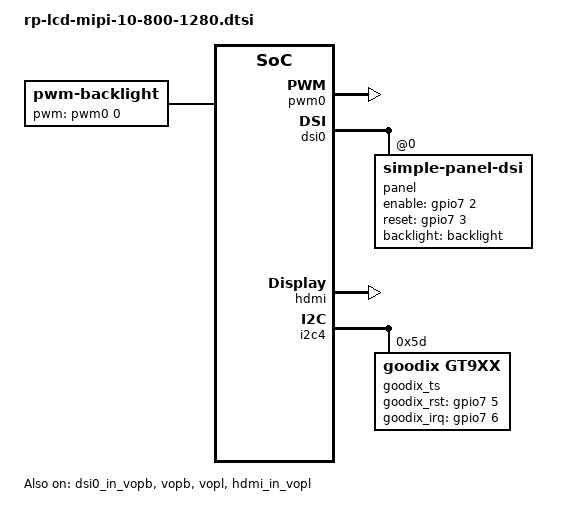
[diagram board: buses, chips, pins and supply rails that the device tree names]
/ {
	display-subsystem {
		status = "okay";

		ports = <&vopb_out>, <&vopl_out>;
		logo-memory-region = <&drm_logo>;

		route {
			route_edp: route-edp {
				status = "disabled";
				logo,uboot = "logo.bmp";
				logo,kernel = "logo.bmp";
				logo,mode = "center";
				charge_logo,mode = "center";
				connect = <&vopb_out_edp>;
			};

			route_dsi0: route-dsi0 {
				status = "disabled";
				logo,uboot = "logo.bmp";
				logo,kernel = "logo.bmp";
				logo,mode = "center";
				charge_logo,mode = "center";
				connect = <&vopb_out_dsi0>;
			};

			route_lvds: route-lvds {
				status = "disabled";
				logo,uboot = "logo.bmp";
				logo,kernel = "logo.bmp";
				logo,mode = "center";
				charge_logo,mode = "center";
				connect = <&vopb_out_lvds>;
			};

			route_hdmi: route-hdmi {
				status = "disabled";
				logo,uboot = "logo.bmp";
				logo,kernel = "logo.bmp";
				logo,mode = "center";
				charge_logo,mode = "center";
				connect = <&vopl_out_hdmi>;
			};
		};
	};
	
	backlight: backlight {
		status = "okay";
		compatible = "pwm-backlight";
		pwms = <&pwm0 0 25000 0>;
		brightness-levels = <
			  0   1   2   3   4   5   6   7
			  8   9  10  11  12  13  14  15
			 16  17  18  19  20  21  22  23
			 24  25  26  27  28  29  30  31
			 32  33  34  35  36  37  38  39
			 40  41  42  43  44  45  46  47
			 48  49  50  51  52  53  54  55
			 56  57  58  59  60  61  62  63
			 64  65  66  67  68  69  70  71
			 72  73  74  75  76  77  78  79
			 80  81  82  83  84  85  86  87
			 88  89  90  91  92  93  94  95
			 96  97  98  99 100 101 102 103
			104 105 106 107 108 109 110 111
			112 113 114 115 116 117 118 119
			120 121 122 123 124 125 126 127
			128 129 130 131 132 133 134 135
			136 137 138 139 140 141 142 143
			144 145 146 147 148 149 150 151
			152 153 154 155 156 157 158 159
			160 161 162 163 164 165 166 167
			168 169 170 171 172 173 174 175
			176 177 178 179 180 181 182 183
			184 185 186 187 188 189 190 191
			192 193 194 195 196 197 198 199
			200 201 202 203 204 205 206 207
			208 209 210 211 212 213 214 215
			216 217 218 219 220 221 222 223
			224 225 226 227 228 229 230 231
			232 233 234 235 236 237 238 239
			240 241 242 243 244 245 246 247
			248 249 250 251 252 253 254 255>;
		default-brightness-level = <255>;
	};
};


&pwm0 {
        status = "okay";
};

&dsi0 {
        status = "okay";
        rockchip,lane-rate = <480>;

        panel: panel {
                compatible = "simple-panel-dsi";
                reg = <0>;
                backlight = <&backlight>;
		cmd_later_reset = <0>;
                enable-gpios = <&gpio7 2 GPIO_ACTIVE_HIGH>;
                reset-gpios = <&gpio7 3 GPIO_ACTIVE_HIGH>;
                dsi,flags = <(MIPI_DSI_MODE_VIDEO | MIPI_DSI_MODE_VIDEO_BURST |
                                MIPI_DSI_MODE_LPM | MIPI_DSI_MODE_EOT_PACKET)>;
                dsi,format = <MIPI_DSI_FMT_RGB888>;
                dsi,lanes = <4>;
                reset-delay-ms = <20>;
                init-delay-ms = <20>;
                enable-delay-ms = <120>;
                prepare-delay-ms = <120>;
				
					
                status = "okay";
		
		panel-init-sequence = [
			15 00 02 e0 00
			15 00 02 e1 93	///0x09>;
			15 00 02 e2 65
			15 00 02 e3 f8
			15 00 02 80 03	///0x02>;	//0x02 = 3lane,0x03 = 4lane
			15 00 02 e0 04
			15 00 02 2d 03
			15 00 02 e0 01
			15 00 02 00 00
			15 00 02 01 5c
			15 00 02 03 00
			15 00 02 04 68
			15 00 02 17 00
			15 00 02 18 d7
			15 00 02 19 01
			15 00 02 1a 00
			15 00 02 1b d7
			15 00 02 1c 01
			15 00 02 1f 6b
			15 00 02 20 29
			15 00 02 21 29
			15 00 02 22 7e
			15 00 02 37 59
			15 00 02 35 28
			15 00 02 38 05
			15 00 02 39 08
			15 00 02 3a 12
			15 00 02 3c 7e
			15 00 02 3d ff
			15 00 02 3e ff
			15 00 02 3f 7f
			15 00 02 40 06
			15 00 02 41 a0
			15 00 02 43 1e
			15 00 02 44 0b
			15 00 02 55 01
			15 00 02 56 01
			15 00 02 57 69
			15 00 02 58 0a
			15 00 02 59 2a
			15 00 02 5a 29
			15 00 02 5b 15
			15 00 02 5c 16
			15 00 02 5d 64
			15 00 02 5e 50
			15 00 02 5f 43
			15 00 02 60 38
			15 00 02 61 36
			15 00 02 62 29
			15 00 02 63 2f
			15 00 02 64 1b
			15 00 02 65 35
			15 00 02 66 35
			15 00 02 67 35
			15 00 02 68 53
			15 00 02 69 41
			15 00 02 6a 47
			15 00 02 6b 38
			15 00 02 6c 34
			15 00 02 6d 27
			15 00 02 6e 19
			15 00 02 6f 12
			15 00 02 70 64
			15 00 02 71 50
			15 00 02 72 43
			15 00 02 73 38
			15 00 02 74 36
			15 00 02 75 29
			15 00 02 76 2f
			15 00 02 77 1b
			15 00 02 78 35
			15 00 02 79 35
			15 00 02 7a 35
			15 00 02 7b 53
			15 00 02 7c 41
			15 00 02 7d 47
			15 00 02 7e 38
			15 00 02 7f 34
			15 00 02 80 27
			15 00 02 81 19
			15 00 02 82 12
			15 00 02 e0 02
			15 00 02 00 53
			15 00 02 01 5f
			15 00 02 02 5f
			15 00 02 03 5f
			15 00 02 04 5f
			15 00 02 05 51
			15 00 02 06 77
			15 00 02 07 57
			15 00 02 08 4f
			15 00 02 09 5f
			15 00 02 0a 4d
			15 00 02 0b 4b
			15 00 02 0c 5f
			15 00 02 0d 49
			15 00 02 0e 47
			15 00 02 0f 45
			15 00 02 10 41
			15 00 02 11 5f
			15 00 02 12 5f
			15 00 02 13 5f
			15 00 02 14 5f
			15 00 02 15 5f
			15 00 02 16 52
			15 00 02 17 5f
			15 00 02 18 5f
			15 00 02 19 5f
			15 00 02 1a 5f
			15 00 02 1b 50
			15 00 02 1c 77
			15 00 02 1d 57
			15 00 02 1e 4e
			15 00 02 1f 5f
			15 00 02 20 4c
			15 00 02 21 4a
			15 00 02 22 5f
			15 00 02 23 48
			15 00 02 24 46
			15 00 02 25 44
			15 00 02 26 40
			15 00 02 27 5f
			15 00 02 28 5f
			15 00 02 29 5f
			15 00 02 2a 5f
			15 00 02 2b 5f
			15 00 02 2c 12
			15 00 02 2d 1f
			15 00 02 2e 1f
			15 00 02 2f 1f
			15 00 02 30 1f
			15 00 02 31 00
			15 00 02 32 17
			15 00 02 33 17
			15 00 02 34 04
			15 00 02 35 1f
			15 00 02 36 06
			15 00 02 37 08
			15 00 02 38 1f
			15 00 02 39 0a
			15 00 02 3a 0c
			15 00 02 3b 0e	///0x01>;
			15 00 02 3c 10
			15 00 02 3d 1f
			15 00 02 3e 1f
			15 00 02 3f 1f
			15 00 02 40 1f
			15 00 02 41 1f
			15 00 02 42 13
			15 00 02 43 1f
			15 00 02 44 1f
			15 00 02 45 1f
			15 00 02 46 1f
			15 00 02 47 01
			15 00 02 48 17
			15 00 02 49 17
			15 00 02 4a 05
			15 00 02 4b 1f
			15 00 02 4c 07
			15 00 02 4d 09
			15 00 02 4e 1f
			15 00 02 4f 0b
			15 00 02 50 0d
			15 00 02 51 0f
			15 00 02 52 11
			15 00 02 53 1f
			15 00 02 54 1f
			15 00 02 55 1f
			15 00 02 56 1f
			15 00 02 57 1f
			15 00 02 58 00
			15 00 02 59 00
			15 00 02 5a 00
			15 00 02 5b 10
			15 00 02 5c 04
			15 00 02 5d 40
			15 00 02 5e 00
			15 00 02 5f 00
			15 00 02 60 40
			15 00 02 61 03
			15 00 02 62 04
			15 00 02 63 70
			15 00 02 64 70
			15 00 02 65 75
			15 00 02 66 0b
			15 00 02 67 b4
			15 00 02 68 06
			15 00 02 69 70
			15 00 02 6a 70
			15 00 02 6b 04
			15 00 02 6c 00
			15 00 02 6d 04
			15 00 02 6e 00
			15 00 02 6f 88
			15 00 02 70 00
			15 00 02 71 00
			15 00 02 72 06
			15 00 02 73 7b
			15 00 02 74 00
			15 00 02 75 bc
			15 00 02 76 00
			15 00 02 77 05
			15 00 02 78 2a
			15 00 02 79 00
			15 00 02 7a 00
			15 00 02 7b 00
			15 00 02 7c 00
			15 00 02 7d 03
			15 00 02 7e 7b
			15 00 02 e0 04
			15 00 02 09 10
			15 00 02 0e 48
			15 00 02 2b 2b
			15 01 02 2e 44
			15 00 02 e0 00
			15 00 02 e6 02
			15 00 02 e7 06
			
			05 78 01 11
			05 78 01 29
			15 0a 02 35 00
		];
		panel-exit-sequence = [
			05 00 01 28
			05 78 01 10
		];

                disp_timings: display-timings {
                        native-mode = <&timing0>;

                        timing0: timing0 {
                                clock-frequency = <68000000>;
                                hactive = <800>;
                                vactive = <1280>;
                                hback-porch = <18>;
                                hfront-porch = <18>;
                                vback-porch = <8>;
                                vfront-porch = <24>;
                                hsync-len = <20>;
                                vsync-len = <4>;
                                hsync-active = <0>;
                                vsync-active = <0>;
                                de-active = <0>;
                                pixelclk-active = <0>;
                        };
                };
        };
};

&route_dsi0 {
        status = "okay";
};
&edp_in_vopl {
        status = "disabled";
};
&dsi0_in_vopl {
        status = "disabled";
};
&dsi1_in_vopl {
        status = "disabled";
};
&lvds_in_vopl {
        status = "disabled";
};

&edp_in_vopb {
        status = "disabled";
};
&dsi0_in_vopb {
        status = "okay";
};
&dsi1_in_vopb {
        status = "disabled";
};
&lvds_in_vopb {
        status = "disabled";
};

&vopb {
	status = "okay";
};

&vopb_mmu {
	status = "okay";
};

&vopl {
	status = "okay";
};

&vopl_mmu {
	status = "okay";
};

&hdmi {
	#address-cells = <1>;
	#size-cells = <0>;
	#sound-dai-cells = <0>;
	status = "okay";
};

&hdmi_in_vopl {
        status = "okay";
};
&hdmi_in_vopb {
        status = "disabled";
};

//TP
&i2c4 {
        status = "okay";
        goodix_ts@5d {
                compatible = "goodix,gt9xx";
                reg = <0x5d>;
		gtp_resolution_x = <800>;
		gtp_resolution_y = <1280>;
		gtp_int_tarigger = <1>;
		gtp_change_x2y = <0>;
		gtp_overturn_x = <0>;
		gtp_overturn_y = <0>;
		gtp_send_cfg = <1>;
		gtp_touch_wakeup = <1>;
                goodix_rst_gpio = <&gpio7 5 GPIO_ACTIVE_HIGH>;
                goodix_irq_gpio = <&gpio7 6 IRQ_TYPE_EDGE_FALLING>;

/* for old touchscreen sensor_id0 */
                goodix,cfg-group0 = [
                        00 20 03 00 05 0A 05 00 01 08 
			28 05 50 32 03 05 00 00 00 00 
			00 00 00 00 00 00 00 90 30 AA 
			17 15 31 0D 00 00 01 B9 04 25 
			00 00 00 00 00 00 00 00 00 00 
			00 0F 23 94 C5 02 07 00 00 04 
			9F 10 00 8B 13 00 7C 16 00 6B 
			1B 00 60 20 00 60 00 00 00 00 
			00 00 00 00 00 00 00 00 00 00 
			00 00 00 00 00 00 00 00 00 00 
			00 00 00 00 00 00 00 00 00 00 
			00 00 19 18 17 16 15 14 11 10 
			0F 0E 0D 0C 09 08 07 06 05 04 
			01 00 00 00 00 00 00 00 00 00 
			00 00 2A 29 28 27 26 25 24 23 
			22 21 20 1F 1E 1C 1B 19 00 02 
			04 06 07 08 0A 0C 0D 0E 0F 10 
			11 12 13 14 00 00 00 00 00 00 
			00 00 00 00 96 01];
/* for new touchscreen sensor_id2 */
                goodix,cfg-group2 = [
                                         00 20 03 00 05 0A 35 00 00
                                         05 28 08 55 41 03 05 00 00
                                         00 00 00 00 00 1A 1C 1E 14
                                         8E 2E 99 14 16 D3 07 00 00
                                         00 9B 02 2D 00 00 00 00 00
                                         00 00 00 00 00 00 0F 23 94
                                         D5 02 07 00 00 04 9D 10 00
                                         86 13 00 75 16 00 61 1B 00
                                         53 20 00 53 00 00 00 00 00
                                         00 00 00 00 00 00 00 00 00
                                         00 00 00 00 00 00 00 00 00
                                         00 00 00 00 00 00 00 00 00
                                         00 00 00 00 17 16 15 14 11
                                         10 0F 0E 0D 0C 09 08 07 06
                                         05 04 01 00 FF FF 00 00 00
                                         00 00 00 00 00 00 00 00 02
                                         04 06 07 08 0A 0C 0D 0F 10
                                         11 12 13 28 27 26 25 24 23
                                         22 21 20 1F 1E 1C 1B 19 FF
                                         FF FF FF 00 00 00 00 00 00
                                         00 00 00 00 4D 01
                                 ];
        };
};
